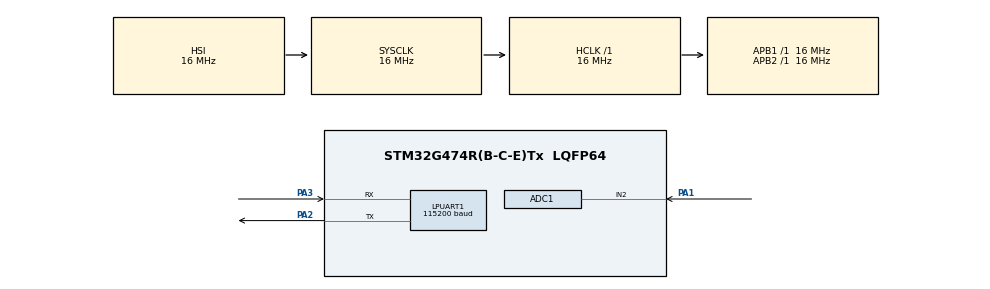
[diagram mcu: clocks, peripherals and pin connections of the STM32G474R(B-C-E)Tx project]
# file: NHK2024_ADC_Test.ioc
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ADC1.Channel-20\#ChannelRegularConversion=ADC_CHANNEL_2
ADC1.ClockPrescaler=ADC_CLOCK_SYNC_PCLK_DIV4
ADC1.NbrOfConversionFlag=1
ADC1.OffsetNumber-20\#ChannelRegularConversion=ADC_OFFSET_NONE
ADC1.OversamplingMode=ENABLE
ADC1.Rank-20\#ChannelRegularConversion=1
ADC1.Ratio=ADC_OVERSAMPLING_RATIO_8
ADC1.Resolution=ADC_RESOLUTION_12B
ADC1.SamplingTime-20\#ChannelRegularConversion=ADC_SAMPLETIME_640CYCLES_5
ADC1.master=1
LPUART1.BaudRate=115200
Mcu.Family=STM32G4
Mcu.Name=STM32G474R(B-C-E)Tx
Mcu.Package=LQFP64
NVIC.PriorityGroup=NVIC_PRIORITYGROUP_4
NVIC.TIM6_DAC_IRQn=true\:0\:0\:false\:false\:true\:true\:true\:true
PA1.Mode=IN2-Single-Ended
PA1.Signal=ADC1_IN2
PA2.Mode=Asynchronous
PA2.Signal=LPUART1_TX
PA3.Mode=Asynchronous
PA3.Signal=LPUART1_RX
ProjectManager.HeapSize=0x200
ProjectManager.StackSize=0x400
ProjectManager.TargetToolchain=STM32CubeIDE
RCC.AHBFreq_Value=16000000
RCC.APB1Freq_Value=16000000
RCC.APB1TimFreq_Value=16000000
RCC.APB2Freq_Value=16000000
RCC.APB2TimFreq_Value=16000000
RCC.CortexFreq_Value=16000000
RCC.EXTERNAL_CLOCK_VALUE=12288000
RCC.HCLKFreq_Value=16000000
RCC.HSE_VALUE=8000000
RCC.HSI48_VALUE=48000000
RCC.HSI_VALUE=16000000
RCC.LSE_VALUE=32768
RCC.SYSCLKFreq_VALUE=16000000
RCC.USBFreq_Value=64000000
RCC.VCOOutputFreq_Value=128000000
TIM6.PeriodNoDither=999
TIM6.Prescaler=16
VP_TIM6_VS_ClockSourceINT.Mode=Enable_Timer
board=custom

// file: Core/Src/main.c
/* USER CODE BEGIN Header */
/**
  ******************************************************************************
  * @file           : main.c
  * @brief          : Main program body
  ******************************************************************************
  * @attention
  *
  * Copyright (c) 2024 STMicroelectronics.
  * All rights reserved.
  *
  * This software is licensed under terms that can be found in the LICENSE file
  * in the root directory of this software component.
  * If no LICENSE file comes with this software, it is provided AS-IS.
  *
  ******************************************************************************
  */
/* USER CODE END Header */
#include "main.h"

/* USER CODE BEGIN Includes */
#include <stdio.h>
#include "filter.h"
//#include "filter.c"
#include "stm32g4xx_ll_system.h"
/* USER CODE END Includes */

ADC_HandleTypeDef hadc1;

UART_HandleTypeDef hlpuart1;

TIM_HandleTypeDef htim6;

/* USER CODE BEGIN PV */
Low_Pass_Filter_Settings* low_pass_filter_settings = NULL;
/* USER CODE END PV */

void SystemClock_Config(void);
static void MX_GPIO_Init(void);
static void MX_LPUART1_UART_Init(void);
static void MX_ADC1_Init(void);
static void MX_TIM6_Init(void);
/* USER CODE BEGIN PFP */
void LOW_PASS_FILTER_INIT(void);
/* USER CODE END PFP */

/* USER CODE BEGIN 0 */
void LOW_PASS_FILTER_INIT(void) {
	/*
	 * 制御周期 : 1000Hz
	 * カットオフ周波数 : 50Hz
	 */
	low_pass_filter_settings = low_pass_filter_init(1e-3, 5e-2);
}

void HAL_TIM_PeriodElapsedCallback(TIM_HandleTypeDef *htim)
{
    if (htim == &htim6){ // 10KHz
    	int val;
    	int filter_val;
    	HAL_ADC_Start(&hadc1);
		if(HAL_ADC_PollForConversion(&hadc1, 10) == HAL_OK) {
			HAL_ADC_Stop(&hadc1);
			val = HAL_ADC_GetValue(&hadc1);
//			filter_val = (int)low_pass_filter_update(low_pass_filter_settings, val);
			printf("%d\r\n", val / 8);
			//ADC変換終了を待機
		} else {
			printf("error\n");
		}
    }
}

int _write(int file, char *ptr, int len)
{
    HAL_UART_Transmit(&hlpuart1,(uint8_t *)ptr,len,8);
    return len;
}
/* USER CODE END 0 */

int main(void)
{

  /* MCU Configuration--------------------------------------------------------*/

  /* Reset of all peripherals, Initializes the Flash interface and the Systick. */
  HAL_Init();

  /* Configure the system clock */
  SystemClock_Config();

  /* Initialize all configured peripherals */
  MX_GPIO_Init();
  MX_LPUART1_UART_Init();
  MX_ADC1_Init();
  MX_TIM6_Init();
  /* USER CODE BEGIN 2 */
  HAL_TIM_Base_Start_IT(&htim6);
  /* USER CODE END 2 */

  /* Infinite loop */
  /* USER CODE BEGIN WHILE */
//  LL_VREFBUF_Enable();
//  LL_VREFBUF_SetVoltageScaling(LL_VREFBUF_VOLTAGE_SCALE2);
//  printf("vrefint %d\r\n", Vrefinit_ADC);
  HAL_ADCEx_Calibration_Start(&hadc1, ADC_SINGLE_ENDED);
  while (1)
  {
//    HAL_ADC_Start(&hadc1);
//	if(HAL_ADC_PollForConversion(&hadc1, HAL_MAX_DELAY) == HAL_OK) {
//		HAL_ADC_Stop(&hadc1);
//		val = HAL_ADC_GetValue(&hadc1);
//		printf("%d\r\n", val);
//		//ADC変換終了を待機
//	} else {
//		printf("error\r\n");
//	}
//
//	HAL_Delay(100);
    /* USER CODE END WHILE */

  }
}

void SystemClock_Config(void)
{
  RCC_OscInitTypeDef RCC_OscInitStruct = {0};
  RCC_ClkInitTypeDef RCC_ClkInitStruct = {0};

  /** Configure the main internal regulator output voltage
  */
  HAL_PWREx_ControlVoltageScaling(PWR_REGULATOR_VOLTAGE_SCALE1);

  /** Initializes the RCC Oscillators according to the specified parameters
  * in the RCC_OscInitTypeDef structure.
  */
  RCC_OscInitStruct.OscillatorType = RCC_OSCILLATORTYPE_HSI;
  RCC_OscInitStruct.HSIState = RCC_HSI_ON;
  RCC_OscInitStruct.HSICalibrationValue = RCC_HSICALIBRATION_DEFAULT;
  RCC_OscInitStruct.PLL.PLLState = RCC_PLL_NONE;
  if (HAL_RCC_OscConfig(&RCC_OscInitStruct) != HAL_OK)
  {
    Error_Handler();
  }

  /** Initializes the CPU, AHB and APB buses clocks
  */
  RCC_ClkInitStruct.ClockType = RCC_CLOCKTYPE_HCLK|RCC_CLOCKTYPE_SYSCLK
                              |RCC_CLOCKTYPE_PCLK1|RCC_CLOCKTYPE_PCLK2;
  RCC_ClkInitStruct.SYSCLKSource = RCC_SYSCLKSOURCE_HSI;
  RCC_ClkInitStruct.AHBCLKDivider = RCC_SYSCLK_DIV1;
  RCC_ClkInitStruct.APB1CLKDivider = RCC_HCLK_DIV1;
  RCC_ClkInitStruct.APB2CLKDivider = RCC_HCLK_DIV1;

  if (HAL_RCC_ClockConfig(&RCC_ClkInitStruct, FLASH_LATENCY_0) != HAL_OK)
  {
    Error_Handler();
  }
}

static void MX_ADC1_Init(void)
{

  ADC_MultiModeTypeDef multimode = {0};
  ADC_ChannelConfTypeDef sConfig = {0};

  /** Common config
  */
  hadc1.Instance = ADC1;
  hadc1.Init.ClockPrescaler = ADC_CLOCK_SYNC_PCLK_DIV4;
  hadc1.Init.Resolution = ADC_RESOLUTION_12B;
  hadc1.Init.DataAlign = ADC_DATAALIGN_RIGHT;
  hadc1.Init.GainCompensation = 0;
  hadc1.Init.ScanConvMode = ADC_SCAN_DISABLE;
  hadc1.Init.EOCSelection = ADC_EOC_SINGLE_CONV;
  hadc1.Init.LowPowerAutoWait = DISABLE;
  hadc1.Init.ContinuousConvMode = DISABLE;
  hadc1.Init.NbrOfConversion = 1;
  hadc1.Init.DiscontinuousConvMode = DISABLE;
  hadc1.Init.ExternalTrigConv = ADC_SOFTWARE_START;
  hadc1.Init.ExternalTrigConvEdge = ADC_EXTERNALTRIGCONVEDGE_NONE;
  hadc1.Init.DMAContinuousRequests = DISABLE;
  hadc1.Init.Overrun = ADC_OVR_DATA_PRESERVED;
  hadc1.Init.OversamplingMode = ENABLE;
  hadc1.Init.Oversampling.Ratio = ADC_OVERSAMPLING_RATIO_8;
  hadc1.Init.Oversampling.RightBitShift = ADC_RIGHTBITSHIFT_NONE;
  hadc1.Init.Oversampling.TriggeredMode = ADC_TRIGGEREDMODE_SINGLE_TRIGGER;
  hadc1.Init.Oversampling.OversamplingStopReset = ADC_REGOVERSAMPLING_CONTINUED_MODE;
  if (HAL_ADC_Init(&hadc1) != HAL_OK)
  {
    Error_Handler();
  }

  /** Configure the ADC multi-mode
  */
  multimode.Mode = ADC_MODE_INDEPENDENT;
  if (HAL_ADCEx_MultiModeConfigChannel(&hadc1, &multimode) != HAL_OK)
  {
    Error_Handler();
  }

  /** Configure Regular Channel
  */
  sConfig.Channel = ADC_CHANNEL_2;
  sConfig.Rank = ADC_REGULAR_RANK_1;
  sConfig.SamplingTime = ADC_SAMPLETIME_640CYCLES_5;
  sConfig.SingleDiff = ADC_SINGLE_ENDED;
  sConfig.OffsetNumber = ADC_OFFSET_NONE;
  sConfig.Offset = 0;
  if (HAL_ADC_ConfigChannel(&hadc1, &sConfig) != HAL_OK)
  {
    Error_Handler();
  }

}

static void MX_LPUART1_UART_Init(void)
{

  hlpuart1.Instance = LPUART1;
  hlpuart1.Init.BaudRate = 115200;
  hlpuart1.Init.WordLength = UART_WORDLENGTH_8B;
  hlpuart1.Init.StopBits = UART_STOPBITS_1;
  hlpuart1.Init.Parity = UART_PARITY_NONE;
  hlpuart1.Init.Mode = UART_MODE_TX_RX;
  hlpuart1.Init.HwFlowCtl = UART_HWCONTROL_NONE;
  hlpuart1.Init.OneBitSampling = UART_ONE_BIT_SAMPLE_DISABLE;
  hlpuart1.Init.ClockPrescaler = UART_PRESCALER_DIV1;
  hlpuart1.AdvancedInit.AdvFeatureInit = UART_ADVFEATURE_NO_INIT;
  if (HAL_UART_Init(&hlpuart1) != HAL_OK)
  {
    Error_Handler();
  }
  if (HAL_UARTEx_SetTxFifoThreshold(&hlpuart1, UART_TXFIFO_THRESHOLD_1_8) != HAL_OK)
  {
    Error_Handler();
  }
  if (HAL_UARTEx_SetRxFifoThreshold(&hlpuart1, UART_RXFIFO_THRESHOLD_1_8) != HAL_OK)
  {
    Error_Handler();
  }
  if (HAL_UARTEx_DisableFifoMode(&hlpuart1) != HAL_OK)
  {
    Error_Handler();
  }

}

static void MX_TIM6_Init(void)
{

  TIM_MasterConfigTypeDef sMasterConfig = {0};

  htim6.Instance = TIM6;
  htim6.Init.Prescaler = 16;
  htim6.Init.CounterMode = TIM_COUNTERMODE_UP;
  htim6.Init.Period = 999;
  htim6.Init.AutoReloadPreload = TIM_AUTORELOAD_PRELOAD_DISABLE;
  if (HAL_TIM_Base_Init(&htim6) != HAL_OK)
  {
    Error_Handler();
  }
  sMasterConfig.MasterOutputTrigger = TIM_TRGO_RESET;
  sMasterConfig.MasterSlaveMode = TIM_MASTERSLAVEMODE_DISABLE;
  if (HAL_TIMEx_MasterConfigSynchronization(&htim6, &sMasterConfig) != HAL_OK)
  {
    Error_Handler();
  }

}

static void MX_GPIO_Init(void)
{

  /* GPIO Ports Clock Enable */
  __HAL_RCC_GPIOA_CLK_ENABLE();

}

void Error_Handler(void)
{
  __disable_irq();
  while (1)
  {
  }
}
